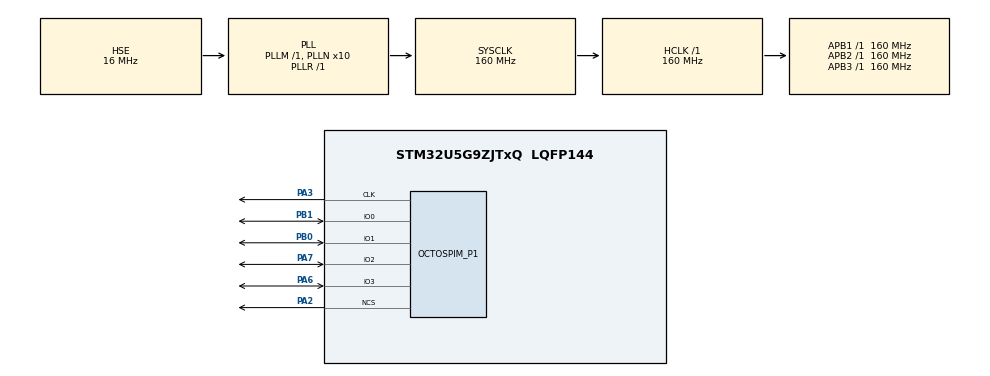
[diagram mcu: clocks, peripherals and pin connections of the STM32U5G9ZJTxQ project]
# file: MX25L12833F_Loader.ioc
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CORTEX_M33_NS.userName=CORTEX_M33
Mcu.Family=STM32U5
Mcu.Name=STM32U5G9ZJTxQ
Mcu.Package=LQFP144
NVIC.PriorityGroup=NVIC_PRIORITYGROUP_4
OCTOSPI1.ChipSelectHighTime=2
OCTOSPI1.ClockPrescaler=4
OCTOSPI1.DeviceSize=24
OCTOSPI1.FifoThreshold=4
OCTOSPI1.MemoryType=HAL_OSPI_MEMTYPE_MACRONIX
OCTOSPI1.SampleShifting=HAL_OSPI_SAMPLE_SHIFTING_NONE
PA2.GPIO_PuPd=GPIO_PULLUP
PA2.GPIO_Speed_High_Default=GPIO_SPEED_FREQ_VERY_HIGH
PA2.Mode=OCTOSPI1_Port1_NCS
PA2.Signal=OCTOSPIM_P1_NCS
PA3.GPIO_PuPd=GPIO_PULLUP
PA3.GPIO_Speed_High_Default=GPIO_SPEED_FREQ_VERY_HIGH
PA3.Mode=O1_P1_CLK
PA3.Signal=OCTOSPIM_P1_CLK
PA6.GPIO_PuPd=GPIO_PULLUP
PA6.GPIO_Speed_High_Default=GPIO_SPEED_FREQ_VERY_HIGH
PA6.Mode=OCTOSPI1_IOL_Port1L
PA6.Signal=OCTOSPIM_P1_IO3
PA7.GPIO_PuPd=GPIO_PULLUP
PA7.GPIO_Speed_High_Default=GPIO_SPEED_FREQ_VERY_HIGH
PA7.Mode=OCTOSPI1_IOL_Port1L
PA7.Signal=OCTOSPIM_P1_IO2
PB0.GPIO_PuPd=GPIO_PULLUP
PB0.GPIO_Speed_High_Default=GPIO_SPEED_FREQ_VERY_HIGH
PB0.Mode=OCTOSPI1_IOL_Port1L
PB0.Signal=OCTOSPIM_P1_IO1
PB1.GPIO_PuPd=GPIO_PULLUP
PB1.GPIO_Speed_High_Default=GPIO_SPEED_FREQ_VERY_HIGH
PB1.Mode=OCTOSPI1_IOL_Port1L
PB1.Signal=OCTOSPIM_P1_IO0
PH0-OSC_IN\ (PH0).Mode=HSE-External-Oscillator
PH0-OSC_IN\ (PH0).Signal=RCC_OSC_IN
PH1-OSC_OUT\ (PH1).Mode=HSE-External-Oscillator
PH1-OSC_OUT\ (PH1).Signal=RCC_OSC_OUT
ProjectManager.HeapSize=0x200
ProjectManager.StackSize=0x400
ProjectManager.TargetToolchain=STM32CubeIDE
RCC.ADCFreq_Value=16000000
RCC.AHBFreq_Value=160000000
RCC.APB1Freq_Value=160000000
RCC.APB1TimFreq_Value=160000000
RCC.APB2Freq_Value=160000000
RCC.APB2TimFreq_Value=160000000
RCC.APB3Freq_Value=160000000
RCC.CortexFreq_Value=160000000
RCC.EPOD_VALUE=16000000
RCC.HCLKFreq_Value=160000000
RCC.HSE_VALUE=16000000
RCC.HSI48_VALUE=48000000
RCC.HSI_VALUE=16000000
RCC.LSE_VALUE=32768
RCC.LSIDIV_VALUE=32000
RCC.MSI_VALUE=4000000
RCC.OCTOSPIMCLockSelection=RCC_OSPICLKSOURCE_PLL1
RCC.PLL1Q=4
RCC.PLL1R=1
RCC.PLL2N=8
RCC.PLL2Q=1
RCC.PLL2Source=RCC_PLLSOURCE_HSE
RCC.PLL3Source=RCC_PLLSOURCE_HSE
RCC.PLLFRACN=0
RCC.PLLN=10
RCC.PLLSourceVirtual=RCC_PLLSOURCE_HSE
RCC.SYSCLKFreq_VALUE=160000000
RCC.SYSCLKSource=RCC_SYSCLKSOURCE_PLLCLK
RCC.VCOOutputFreq_Value=160000000
VP_LPBAMQUEUE_VS_QUEUE.Mode=QUEUEMODE
VP_LPBAM_VS_SIG1.Mode=SmartRun
VP_LPBAM_VS_SIG4.Mode=LPDMA1
VP_MEMORYMAP_VS_MEMORYMAP.Mode=CurAppReg
VP_OCTOSPI1_VS_quad.Mode=quad_mode
VP_PWR_VS_SECSignals.Mode=Security/Privilege
board=custom

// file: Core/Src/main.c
/* USER CODE BEGIN Header */
/**
  ******************************************************************************
  * @file           : main.c
  * @brief          : Main program body
  ******************************************************************************
  * @attention
  *
  * Copyright (c) 2025 STMicroelectronics.
  * All rights reserved.
  *
  * This software is licensed under terms that can be found in the LICENSE file
  * in the root directory of this software component.
  * If no LICENSE file comes with this software, it is provided AS-IS.
  *
  ******************************************************************************
  */
/* USER CODE END Header */
#include "main.h"
#include "memorymap.h"
#include "octospi.h"
#include "gpio.h"

void SystemClock_Config(void);

int main(void)
{

  /* MCU Configuration--------------------------------------------------------*/

  /* Reset of all peripherals, Initializes the Flash interface and the Systick. */
  HAL_Init();

  /* Configure the system clock */
  SystemClock_Config();

  /* Initialize all configured peripherals */
  MX_GPIO_Init();
//  MX_OCTOSPI1_Init();

  /* Infinite loop */
  while (1)
  {

  }
}

void SystemClock_Config(void)
{
  RCC_OscInitTypeDef RCC_OscInitStruct = {0};
  RCC_ClkInitTypeDef RCC_ClkInitStruct = {0};

  /** Configure the main internal regulator output voltage
  */
  if (HAL_PWREx_ControlVoltageScaling(PWR_REGULATOR_VOLTAGE_SCALE1) != HAL_OK)
  {
    Error_Handler();
  }

  /** Initializes the CPU, AHB and APB buses clocks
  */
  RCC_OscInitStruct.OscillatorType = RCC_OSCILLATORTYPE_HSE;
  RCC_OscInitStruct.HSEState = RCC_HSE_ON;
  RCC_OscInitStruct.PLL.PLLState = RCC_PLL_ON;
  RCC_OscInitStruct.PLL.PLLSource = RCC_PLLSOURCE_HSE;
  RCC_OscInitStruct.PLL.PLLMBOOST = RCC_PLLMBOOST_DIV1;
  RCC_OscInitStruct.PLL.PLLM = 1;
  RCC_OscInitStruct.PLL.PLLN = 10;
  RCC_OscInitStruct.PLL.PLLP = 2;
  RCC_OscInitStruct.PLL.PLLQ = 4;
  RCC_OscInitStruct.PLL.PLLR = 1;
  RCC_OscInitStruct.PLL.PLLRGE = RCC_PLLVCIRANGE_1;
  RCC_OscInitStruct.PLL.PLLFRACN = 0;
  if (HAL_RCC_OscConfig(&RCC_OscInitStruct) != HAL_OK)
  {
    Error_Handler();
  }

  /** Initializes the CPU, AHB and APB buses clocks
  */
  RCC_ClkInitStruct.ClockType = RCC_CLOCKTYPE_HCLK|RCC_CLOCKTYPE_SYSCLK
                              |RCC_CLOCKTYPE_PCLK1|RCC_CLOCKTYPE_PCLK2
                              |RCC_CLOCKTYPE_PCLK3;
  RCC_ClkInitStruct.SYSCLKSource = RCC_SYSCLKSOURCE_PLLCLK;
  RCC_ClkInitStruct.AHBCLKDivider = RCC_SYSCLK_DIV1;
  RCC_ClkInitStruct.APB1CLKDivider = RCC_HCLK_DIV1;
  RCC_ClkInitStruct.APB2CLKDivider = RCC_HCLK_DIV1;
  RCC_ClkInitStruct.APB3CLKDivider = RCC_HCLK_DIV1;

  if (HAL_RCC_ClockConfig(&RCC_ClkInitStruct, FLASH_LATENCY_4) != HAL_OK)
  {
    Error_Handler();
  }
}

void Error_Handler(void)
{
  /* USER CODE BEGIN Error_Handler_Debug */
  /* User can add his own implementation to report the HAL error return state */
//  __disable_irq();
//  while (1)
//  {
//  }
	return;
  /* USER CODE END Error_Handler_Debug */
}
